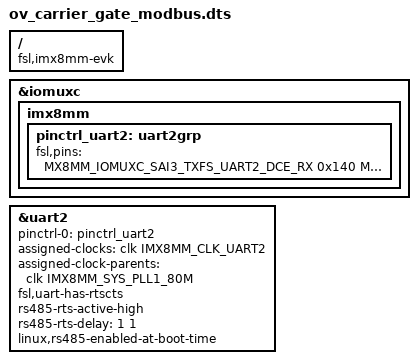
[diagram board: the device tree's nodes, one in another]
/**
 * Portenta-M8 dtb overlay file
 * Arduino 2021
 * Enable UART1 on Arduino Breakout carrier board
 */

/dts-v1/;
/plugin/;

#include <dt-bindings/clock/imx8mm-clock.h>
#include "imx8mm-pinfunc.h"
#include "imx8mm-pinfunc.h"
#include <dt-bindings/gpio/gpio.h>

/ {
	compatible = "fsl,imx8mm-evk", "fsl,imx8mm";

	fragment@0 {
		target = <&iomuxc>;
		__overlay__ {
			imx8mm {
				pinctrl_uart2: uart2grp {
					fsl,pins = <
						MX8MM_IOMUXC_SAI3_TXFS_UART2_DCE_RX		0x140
						MX8MM_IOMUXC_SAI3_TXC_UART2_DCE_TX		0x140
						MX8MM_IOMUXC_SAI3_RXD_UART2_DCE_RTS_B	0x140
						MX8MM_IOMUXC_SAI3_RXC_UART2_DCE_CTS_B	0x140
						/*
						MX8MM_IOMUXC_SAI3_RXC_GPIO4_IO29		0x19
						MX8MM_IOMUXC_SAI3_RXD_GPIO4_IO30		0x151
						MX8MM_IOMUXC_SAI3_RXD_GPIO4_IO30		0x19
						*/
					>;
				};
			};
		};
	};

	fragment@1 {
		target = <&uart2>;
		__overlay__ {
			pinctrl-names = "default";
			pinctrl-0 = <&pinctrl_uart2>;
			assigned-clocks = <&clk IMX8MM_CLK_UART2>;
			assigned-clock-parents = <&clk IMX8MM_SYS_PLL1_80M>;
			fsl,uart-has-rtscts;
			/*
			fsl,rts-gpios=<&gpio4 30 GPIO_ACTIVE_LOW>;
			fsl,rts-gpios=<&gpio4 29 GPIO_ACTIVE_HIGH>;
			*/
			rs485-rts-active-high;
			rs485-rts-delay = <1 1>;
			/*
			fsl,inverted-tx;
			fsl,inverted-rx;
			*/
			linux,rs485-enabled-at-boot-time;
			status = "okay";
		};
	};
};
